AUTOSAR XML (schema 00046)
package /EcuExtract
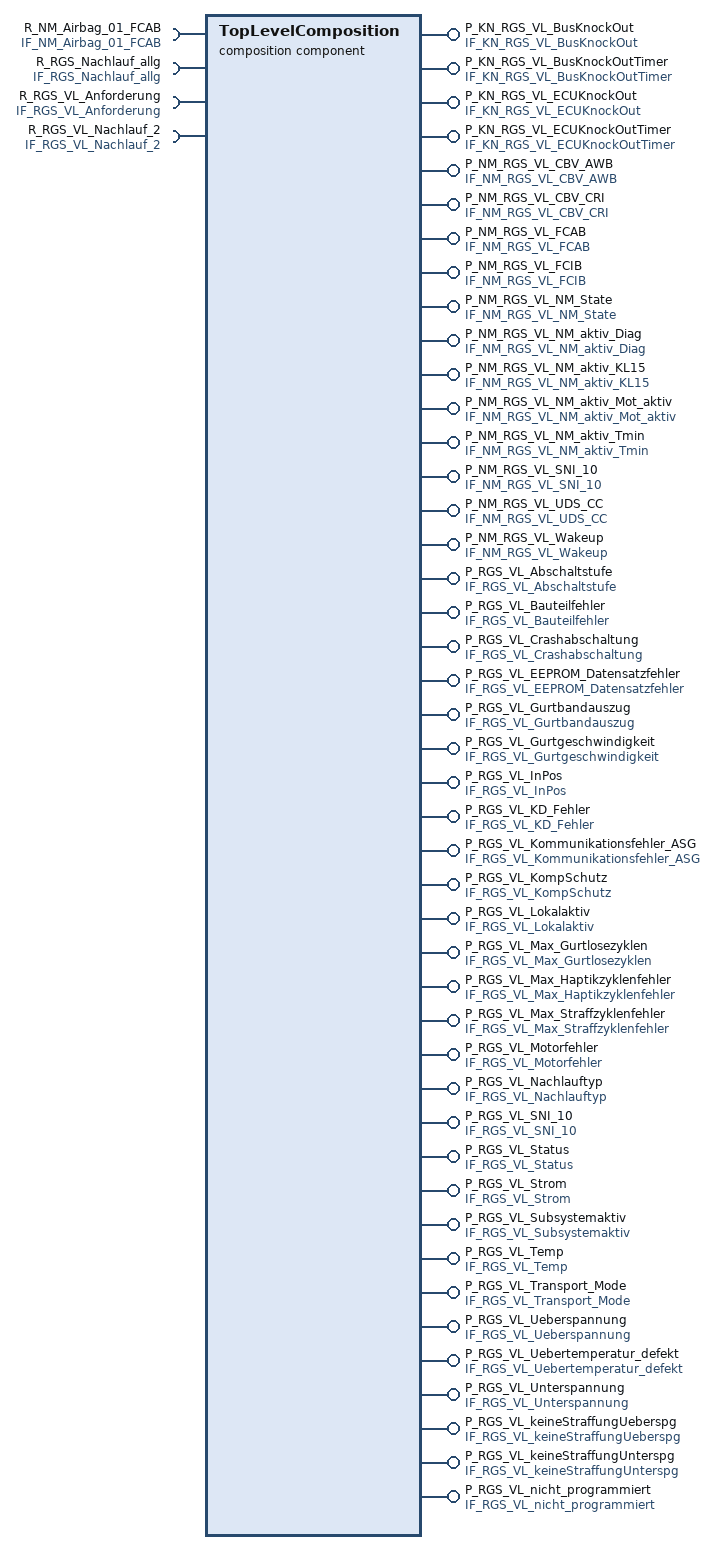
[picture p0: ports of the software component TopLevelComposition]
  composition sw component type TopLevelComposition
    44 x provide port:
      P_KN_RGS_VL_BusKnockOut: provided-interface=IF_KN_RGS_VL_BusKnockOut
      P_KN_RGS_VL_BusKnockOutTimer: provided-interface=IF_KN_RGS_VL_BusKnockOutTimer
      P_KN_RGS_VL_ECUKnockOut: provided-interface=IF_KN_RGS_VL_ECUKnockOut
      P_KN_RGS_VL_ECUKnockOutTimer: provided-interface=IF_KN_RGS_VL_ECUKnockOutTimer
      P_NM_RGS_VL_CBV_AWB: provided-interface=IF_NM_RGS_VL_CBV_AWB
      P_NM_RGS_VL_CBV_CRI: provided-interface=IF_NM_RGS_VL_CBV_CRI
      P_NM_RGS_VL_FCAB: provided-interface=IF_NM_RGS_VL_FCAB
      P_NM_RGS_VL_FCIB: provided-interface=IF_NM_RGS_VL_FCIB
      P_NM_RGS_VL_NM_State: provided-interface=IF_NM_RGS_VL_NM_State
      P_NM_RGS_VL_NM_aktiv_Diag: provided-interface=IF_NM_RGS_VL_NM_aktiv_Diag
      P_NM_RGS_VL_NM_aktiv_KL15: provided-interface=IF_NM_RGS_VL_NM_aktiv_KL15
      P_NM_RGS_VL_NM_aktiv_Mot_aktiv: provided-interface=IF_NM_RGS_VL_NM_aktiv_Mot_aktiv
      P_NM_RGS_VL_NM_aktiv_Tmin: provided-interface=IF_NM_RGS_VL_NM_aktiv_Tmin
      P_NM_RGS_VL_SNI_10: provided-interface=IF_NM_RGS_VL_SNI_10
      P_NM_RGS_VL_UDS_CC: provided-interface=IF_NM_RGS_VL_UDS_CC
      P_NM_RGS_VL_Wakeup: provided-interface=IF_NM_RGS_VL_Wakeup
      P_RGS_VL_Abschaltstufe: provided-interface=IF_RGS_VL_Abschaltstufe
      P_RGS_VL_Bauteilfehler: provided-interface=IF_RGS_VL_Bauteilfehler
      P_RGS_VL_Crashabschaltung: provided-interface=IF_RGS_VL_Crashabschaltung
      P_RGS_VL_EEPROM_Datensatzfehler: provided-interface=IF_RGS_VL_EEPROM_Datensatzfehler
      P_RGS_VL_Gurtbandauszug: provided-interface=IF_RGS_VL_Gurtbandauszug
      P_RGS_VL_Gurtgeschwindigkeit: provided-interface=IF_RGS_VL_Gurtgeschwindigkeit
      P_RGS_VL_InPos: provided-interface=IF_RGS_VL_InPos
      P_RGS_VL_KD_Fehler: provided-interface=IF_RGS_VL_KD_Fehler
      P_RGS_VL_Kommunikationsfehler_ASG: provided-interface=IF_RGS_VL_Kommunikationsfehler_ASG
      P_RGS_VL_KompSchutz: provided-interface=IF_RGS_VL_KompSchutz
      P_RGS_VL_Lokalaktiv: provided-interface=IF_RGS_VL_Lokalaktiv
      P_RGS_VL_Max_Gurtlosezyklen: provided-interface=IF_RGS_VL_Max_Gurtlosezyklen
      P_RGS_VL_Max_Haptikzyklenfehler: provided-interface=IF_RGS_VL_Max_Haptikzyklenfehler
      P_RGS_VL_Max_Straffzyklenfehler: provided-interface=IF_RGS_VL_Max_Straffzyklenfehler
      P_RGS_VL_Motorfehler: provided-interface=IF_RGS_VL_Motorfehler
      P_RGS_VL_Nachlauftyp: provided-interface=IF_RGS_VL_Nachlauftyp
      P_RGS_VL_SNI_10: provided-interface=IF_RGS_VL_SNI_10
      P_RGS_VL_Status: provided-interface=IF_RGS_VL_Status
      P_RGS_VL_Strom: provided-interface=IF_RGS_VL_Strom
      P_RGS_VL_Subsystemaktiv: provided-interface=IF_RGS_VL_Subsystemaktiv
      P_RGS_VL_Temp: provided-interface=IF_RGS_VL_Temp
      P_RGS_VL_Transport_Mode: provided-interface=IF_RGS_VL_Transport_Mode
      P_RGS_VL_Ueberspannung: provided-interface=IF_RGS_VL_Ueberspannung
      P_RGS_VL_Uebertemperatur_defekt: provided-interface=IF_RGS_VL_Uebertemperatur_defekt
      P_RGS_VL_Unterspannung: provided-interface=IF_RGS_VL_Unterspannung
      P_RGS_VL_keineStraffungUeberspg: provided-interface=IF_RGS_VL_keineStraffungUeberspg
      P_RGS_VL_keineStraffungUnterspg: provided-interface=IF_RGS_VL_keineStraffungUnterspg
      P_RGS_VL_nicht_programmiert: provided-interface=IF_RGS_VL_nicht_programmiert
    4 x require port:
      R_NM_Airbag_01_FCAB: required-interface=IF_NM_Airbag_01_FCAB
      R_RGS_Nachlauf_allg: required-interface=IF_RGS_Nachlauf_allg
      R_RGS_VL_Anforderung: required-interface=IF_RGS_VL_Anforderung
      R_RGS_VL_Nachlauf_2: required-interface=IF_RGS_VL_Nachlauf_2
    11 x component:
      BswM_Prototype: type=BswM
      ComM_Prototype: type=ComM
      Dem_Prototype: type=Dem
      Dcm_Prototype: type=Dcm
      EcuM_Prototype: type=EcuM
      DiagDt_Prototype: type=DiagDt
      NmUsrDt_SwCType_Prototype: type=NmUsrDt_SwCType
      DiagDt_DiagExt_Prototype: type=DiagDt_DiagExt
      BusMon_SwCType_Prototype: type=BusMon_SwCType
      VoltMon_Prototype: type=VoltMon
      TestSwc: type=TestSwc_RGS_VL
    delegate TestSwc.P_KN_RGS_VL_BusKnockOut <-> outer port P_KN_RGS_VL_BusKnockOut
    delegate TestSwc.P_KN_RGS_VL_BusKnockOutTimer <-> outer port P_KN_RGS_VL_BusKnockOutTimer
    delegate TestSwc.P_KN_RGS_VL_ECUKnockOut <-> outer port P_KN_RGS_VL_ECUKnockOut
    delegate TestSwc.P_KN_RGS_VL_ECUKnockOutTimer <-> outer port P_KN_RGS_VL_ECUKnockOutTimer
    delegate TestSwc.P_NM_RGS_VL_CBV_AWB <-> outer port P_NM_RGS_VL_CBV_AWB
    delegate TestSwc.P_NM_RGS_VL_CBV_CRI <-> outer port P_NM_RGS_VL_CBV_CRI
    delegate TestSwc.P_NM_RGS_VL_FCAB <-> outer port P_NM_RGS_VL_FCAB
    delegate TestSwc.P_NM_RGS_VL_FCIB <-> outer port P_NM_RGS_VL_FCIB
    delegate TestSwc.P_NM_RGS_VL_NM_State <-> outer port P_NM_RGS_VL_NM_State
    delegate TestSwc.P_NM_RGS_VL_NM_aktiv_Diag <-> outer port P_NM_RGS_VL_NM_aktiv_Diag
    delegate TestSwc.P_NM_RGS_VL_NM_aktiv_KL15 <-> outer port P_NM_RGS_VL_NM_aktiv_KL15
    delegate TestSwc.P_NM_RGS_VL_NM_aktiv_Mot_aktiv <-> outer port P_NM_RGS_VL_NM_aktiv_Mot_aktiv
    delegate TestSwc.P_NM_RGS_VL_NM_aktiv_Tmin <-> outer port P_NM_RGS_VL_NM_aktiv_Tmin
    delegate TestSwc.P_NM_RGS_VL_SNI_10 <-> outer port P_NM_RGS_VL_SNI_10
    delegate TestSwc.P_NM_RGS_VL_UDS_CC <-> outer port P_NM_RGS_VL_UDS_CC
    delegate TestSwc.P_NM_RGS_VL_Wakeup <-> outer port P_NM_RGS_VL_Wakeup
    delegate TestSwc.P_RGS_VL_Abschaltstufe <-> outer port P_RGS_VL_Abschaltstufe
    delegate TestSwc.P_RGS_VL_Bauteilfehler <-> outer port P_RGS_VL_Bauteilfehler
    delegate TestSwc.P_RGS_VL_Crashabschaltung <-> outer port P_RGS_VL_Crashabschaltung
    delegate TestSwc.P_RGS_VL_EEPROM_Datensatzfehler <-> outer port P_RGS_VL_EEPROM_Datensatzfehler
    delegate TestSwc.P_RGS_VL_Gurtbandauszug <-> outer port P_RGS_VL_Gurtbandauszug
    delegate TestSwc.P_RGS_VL_Gurtgeschwindigkeit <-> outer port P_RGS_VL_Gurtgeschwindigkeit
    delegate TestSwc.P_RGS_VL_InPos <-> outer port P_RGS_VL_InPos
    delegate TestSwc.P_RGS_VL_KD_Fehler <-> outer port P_RGS_VL_KD_Fehler
    delegate TestSwc.P_RGS_VL_Kommunikationsfehler_ASG <-> outer port P_RGS_VL_Kommunikationsfehler_ASG
    delegate TestSwc.P_RGS_VL_KompSchutz <-> outer port P_RGS_VL_KompSchutz
    delegate TestSwc.P_RGS_VL_Lokalaktiv <-> outer port P_RGS_VL_Lokalaktiv
    delegate TestSwc.P_RGS_VL_Max_Gurtlosezyklen <-> outer port P_RGS_VL_Max_Gurtlosezyklen
    delegate TestSwc.P_RGS_VL_Max_Haptikzyklenfehler <-> outer port P_RGS_VL_Max_Haptikzyklenfehler
    delegate TestSwc.P_RGS_VL_Max_Straffzyklenfehler <-> outer port P_RGS_VL_Max_Straffzyklenfehler
    delegate TestSwc.P_RGS_VL_Motorfehler <-> outer port P_RGS_VL_Motorfehler
    delegate TestSwc.P_RGS_VL_Nachlauftyp <-> outer port P_RGS_VL_Nachlauftyp
    delegate TestSwc.P_RGS_VL_SNI_10 <-> outer port P_RGS_VL_SNI_10
    delegate TestSwc.P_RGS_VL_Status <-> outer port P_RGS_VL_Status
    delegate TestSwc.P_RGS_VL_Strom <-> outer port P_RGS_VL_Strom
    delegate TestSwc.P_RGS_VL_Subsystemaktiv <-> outer port P_RGS_VL_Subsystemaktiv
    delegate TestSwc.P_RGS_VL_Temp <-> outer port P_RGS_VL_Temp
    delegate TestSwc.P_RGS_VL_Transport_Mode <-> outer port P_RGS_VL_Transport_Mode
    delegate TestSwc.P_RGS_VL_Ueberspannung <-> outer port P_RGS_VL_Ueberspannung
    delegate TestSwc.P_RGS_VL_Uebertemperatur_defekt <-> outer port P_RGS_VL_Uebertemperatur_defekt
    delegate TestSwc.P_RGS_VL_Unterspannung <-> outer port P_RGS_VL_Unterspannung
    delegate TestSwc.P_RGS_VL_keineStraffungUeberspg <-> outer port P_RGS_VL_keineStraffungUeberspg
    delegate TestSwc.P_RGS_VL_keineStraffungUnterspg <-> outer port P_RGS_VL_keineStraffungUnterspg
    delegate TestSwc.P_RGS_VL_nicht_programmiert <-> outer port P_RGS_VL_nicht_programmiert
    delegate TestSwc.R_NM_Airbag_01_FCAB <-> outer port R_NM_Airbag_01_FCAB
    delegate TestSwc.R_RGS_Nachlauf_allg <-> outer port R_RGS_Nachlauf_allg
    delegate TestSwc.R_RGS_VL_Anforderung <-> outer port R_RGS_VL_Anforderung
    delegate TestSwc.R_RGS_VL_Nachlauf_2 <-> outer port R_RGS_VL_Nachlauf_2
  system ECU: category=ECU_EXTRACT, system-version=1.0.0
    48 x system mapping:
      DataMappings_P_KN_RGS_VL_BusKnockOut: sender-receiver-to-signal-mapping{data-element=TopLevelCompositionPrototype.P_KN_RGS_VL_BusKnockOut.KN_RGS_VL_BusKnockOut, system-signal=KN_RGS_VL_BusKnockOut}
      DataMappings_P_KN_RGS_VL_BusKnockOutTimer: sender-receiver-to-signal-mapping{data-element=TopLevelCompositionPrototype.P_KN_RGS_VL_BusKnockOutTimer.KN_RGS_VL_BusKnockOutTimer, system-signal=KN_RGS_VL_BusKnockOutTimer}
      DataMappings_P_KN_RGS_VL_ECUKnockOut: sender-receiver-to-signal-mapping{data-element=TopLevelCompositionPrototype.P_KN_RGS_VL_ECUKnockOut.KN_RGS_VL_ECUKnockOut, system-signal=KN_RGS_VL_ECUKnockOut}
      DataMappings_P_KN_RGS_VL_ECUKnockOutTimer: sender-receiver-to-signal-mapping{data-element=TopLevelCompositionPrototype.P_KN_RGS_VL_ECUKnockOutTimer.KN_RGS_VL_ECUKnockOutTimer, system-signal=KN_RGS_VL_ECUKnockOutTimer}
      DataMappings_P_NM_RGS_VL_CBV_AWB: sender-receiver-to-signal-mapping{data-element=TopLevelCompositionPrototype.P_NM_RGS_VL_CBV_AWB.NM_RGS_VL_CBV_AWB, system-signal=NM_RGS_VL_CBV_AWB}
      DataMappings_P_NM_RGS_VL_CBV_CRI: sender-receiver-to-signal-mapping{data-element=TopLevelCompositionPrototype.P_NM_RGS_VL_CBV_CRI.NM_RGS_VL_CBV_CRI, system-signal=NM_RGS_VL_CBV_CRI}
      DataMappings_P_NM_RGS_VL_FCAB: sender-receiver-to-signal-mapping{data-element=TopLevelCompositionPrototype.P_NM_RGS_VL_FCAB.NM_RGS_VL_FCAB, system-signal=NM_RGS_VL_FCAB}
      DataMappings_P_NM_RGS_VL_FCIB: sender-receiver-to-signal-mapping{data-element=TopLevelCompositionPrototype.P_NM_RGS_VL_FCIB.NM_RGS_VL_FCIB, system-signal=NM_RGS_VL_FCIB}
      DataMappings_P_NM_RGS_VL_NM_State: sender-receiver-to-signal-mapping{data-element=TopLevelCompositionPrototype.P_NM_RGS_VL_NM_State.NM_RGS_VL_NM_State, system-signal=NM_RGS_VL_NM_State}
      DataMappings_P_NM_RGS_VL_NM_aktiv_Diag: sender-receiver-to-signal-mapping{data-element=TopLevelCompositionPrototype.P_NM_RGS_VL_NM_aktiv_Diag.NM_RGS_VL_NM_aktiv_Diag, system-signal=NM_RGS_VL_NM_aktiv_Diag}
      DataMappings_P_NM_RGS_VL_NM_aktiv_KL15: sender-receiver-to-signal-mapping{data-element=TopLevelCompositionPrototype.P_NM_RGS_VL_NM_aktiv_KL15.NM_RGS_VL_NM_aktiv_KL15, system-signal=NM_RGS_VL_NM_aktiv_KL15}
      DataMappings_P_NM_RGS_VL_NM_aktiv_Mot_aktiv: sender-receiver-to-signal-mapping{data-element=TopLevelCompositionPrototype.P_NM_RGS_VL_NM_aktiv_Mot_aktiv.NM_RGS_VL_NM_aktiv_Mot_aktiv, system-signal=NM_RGS_VL_NM_aktiv_Mot_aktiv}
      DataMappings_P_NM_RGS_VL_NM_aktiv_Tmin: sender-receiver-to-signal-mapping{data-element=TopLevelCompositionPrototype.P_NM_RGS_VL_NM_aktiv_Tmin.NM_RGS_VL_NM_aktiv_Tmin, system-signal=NM_RGS_VL_NM_aktiv_Tmin}
      DataMappings_P_NM_RGS_VL_SNI_10: sender-receiver-to-signal-mapping{data-element=TopLevelCompositionPrototype.P_NM_RGS_VL_SNI_10.NM_RGS_VL_SNI_10, system-signal=NM_RGS_VL_SNI_10}
      DataMappings_P_NM_RGS_VL_UDS_CC: sender-receiver-to-signal-mapping{data-element=TopLevelCompositionPrototype.P_NM_RGS_VL_UDS_CC.NM_RGS_VL_UDS_CC, system-signal=NM_RGS_VL_UDS_CC}
      DataMappings_P_NM_RGS_VL_Wakeup: sender-receiver-to-signal-mapping{data-element=TopLevelCompositionPrototype.P_NM_RGS_VL_Wakeup.NM_RGS_VL_Wakeup, system-signal=NM_RGS_VL_Wakeup}
      DataMappings_P_RGS_VL_Abschaltstufe: sender-receiver-to-signal-mapping{data-element=TopLevelCompositionPrototype.P_RGS_VL_Abschaltstufe.RGS_VL_Abschaltstufe, system-signal=RGS_VL_Abschaltstufe}
      DataMappings_P_RGS_VL_Bauteilfehler: sender-receiver-to-signal-mapping{data-element=TopLevelCompositionPrototype.P_RGS_VL_Bauteilfehler.RGS_VL_Bauteilfehler, system-signal=RGS_VL_Bauteilfehler}
      DataMappings_P_RGS_VL_Crashabschaltung: sender-receiver-to-signal-mapping{data-element=TopLevelCompositionPrototype.P_RGS_VL_Crashabschaltung.RGS_VL_Crashabschaltung, system-signal=RGS_VL_Crashabschaltung}
      DataMappings_P_RGS_VL_EEPROM_Datensatzfehler: sender-receiver-to-signal-mapping{data-element=TopLevelCompositionPrototype.P_RGS_VL_EEPROM_Datensatzfehler.RGS_VL_EEPROM_Datensatzfehler, system-signal=RGS_VL_EEPROM_Datensatzfehler}
      DataMappings_P_RGS_VL_Gurtbandauszug: sender-receiver-to-signal-mapping{data-element=TopLevelCompositionPrototype.P_RGS_VL_Gurtbandauszug.RGS_VL_Gurtbandauszug, system-signal=RGS_VL_Gurtbandauszug}
      DataMappings_P_RGS_VL_Gurtgeschwindigkeit: sender-receiver-to-signal-mapping{data-element=TopLevelCompositionPrototype.P_RGS_VL_Gurtgeschwindigkeit.RGS_VL_Gurtgeschwindigkeit, system-signal=RGS_VL_Gurtgeschwindigkeit}
      DataMappings_P_RGS_VL_InPos: sender-receiver-to-signal-mapping{data-element=TopLevelCompositionPrototype.P_RGS_VL_InPos.RGS_VL_InPos, system-signal=RGS_VL_InPos}
      DataMappings_P_RGS_VL_KD_Fehler: sender-receiver-to-signal-mapping{data-element=TopLevelCompositionPrototype.P_RGS_VL_KD_Fehler.RGS_VL_KD_Fehler, system-signal=RGS_VL_KD_Fehler}
      DataMappings_P_RGS_VL_Kommunikationsfehler_ASG: sender-receiver-to-signal-mapping{data-element=TopLevelCompositionPrototype.P_RGS_VL_Kommunikationsfehler_ASG.RGS_VL_Kommunikationsfehler_ASG, system-signal=RGS_VL_Kommunikationsfehler_ASG}
      DataMappings_P_RGS_VL_KompSchutz: sender-receiver-to-signal-mapping{data-element=TopLevelCompositionPrototype.P_RGS_VL_KompSchutz.RGS_VL_KompSchutz, system-signal=RGS_VL_KompSchutz}
      DataMappings_P_RGS_VL_Lokalaktiv: sender-receiver-to-signal-mapping{data-element=TopLevelCompositionPrototype.P_RGS_VL_Lokalaktiv.RGS_VL_Lokalaktiv, system-signal=RGS_VL_Lokalaktiv}
      DataMappings_P_RGS_VL_Max_Gurtlosezyklen: sender-receiver-to-signal-mapping{data-element=TopLevelCompositionPrototype.P_RGS_VL_Max_Gurtlosezyklen.RGS_VL_Max_Gurtlosezyklen, system-signal=RGS_VL_Max_Gurtlosezyklen}
      DataMappings_P_RGS_VL_Max_Haptikzyklenfehler: sender-receiver-to-signal-mapping{data-element=TopLevelCompositionPrototype.P_RGS_VL_Max_Haptikzyklenfehler.RGS_VL_Max_Haptikzyklenfehler, system-signal=RGS_VL_Max_Haptikzyklenfehler}
      DataMappings_P_RGS_VL_Max_Straffzyklenfehler: sender-receiver-to-signal-mapping{data-element=TopLevelCompositionPrototype.P_RGS_VL_Max_Straffzyklenfehler.RGS_VL_Max_Straffzyklenfehler, system-signal=RGS_VL_Max_Straffzyklenfehler}
      DataMappings_P_RGS_VL_Motorfehler: sender-receiver-to-signal-mapping{data-element=TopLevelCompositionPrototype.P_RGS_VL_Motorfehler.RGS_VL_Motorfehler, system-signal=RGS_VL_Motorfehler}
      DataMappings_P_RGS_VL_Nachlauftyp: sender-receiver-to-signal-mapping{data-element=TopLevelCompositionPrototype.P_RGS_VL_Nachlauftyp.RGS_VL_Nachlauftyp, system-signal=RGS_VL_Nachlauftyp}
      DataMappings_P_RGS_VL_SNI_10: sender-receiver-to-signal-mapping{data-element=TopLevelCompositionPrototype.P_RGS_VL_SNI_10.RGS_VL_SNI_10, system-signal=RGS_VL_SNI_10}
      DataMappings_P_RGS_VL_Status: sender-receiver-to-signal-mapping{data-element=TopLevelCompositionPrototype.P_RGS_VL_Status.RGS_VL_Status, system-signal=RGS_VL_Status}
      DataMappings_P_RGS_VL_Strom: sender-receiver-to-signal-mapping{data-element=TopLevelCompositionPrototype.P_RGS_VL_Strom.RGS_VL_Strom, system-signal=RGS_VL_Strom}
      DataMappings_P_RGS_VL_Subsystemaktiv: sender-receiver-to-signal-mapping{data-element=TopLevelCompositionPrototype.P_RGS_VL_Subsystemaktiv.RGS_VL_Subsystemaktiv, system-signal=RGS_VL_Subsystemaktiv}
      DataMappings_P_RGS_VL_Temp: sender-receiver-to-signal-mapping{data-element=TopLevelCompositionPrototype.P_RGS_VL_Temp.RGS_VL_Temp, system-signal=RGS_VL_Temp}
      DataMappings_P_RGS_VL_Transport_Mode: sender-receiver-to-signal-mapping{data-element=TopLevelCompositionPrototype.P_RGS_VL_Transport_Mode.RGS_VL_Transport_Mode, system-signal=RGS_VL_Transport_Mode}
      DataMappings_P_RGS_VL_Ueberspannung: sender-receiver-to-signal-mapping{data-element=TopLevelCompositionPrototype.P_RGS_VL_Ueberspannung.RGS_VL_Ueberspannung, system-signal=RGS_VL_Ueberspannung}
      DataMappings_P_RGS_VL_Uebertemperatur_defekt: sender-receiver-to-signal-mapping{data-element=TopLevelCompositionPrototype.P_RGS_VL_Uebertemperatur_defekt.RGS_VL_Uebertemperatur_defekt, system-signal=RGS_VL_Uebertemperatur_defekt}
      DataMappings_P_RGS_VL_Unterspannung: sender-receiver-to-signal-mapping{data-element=TopLevelCompositionPrototype.P_RGS_VL_Unterspannung.RGS_VL_Unterspannung, system-signal=RGS_VL_Unterspannung}
      DataMappings_P_RGS_VL_keineStraffungUeberspg: sender-receiver-to-signal-mapping{data-element=TopLevelCompositionPrototype.P_RGS_VL_keineStraffungUeberspg.RGS_VL_keineStraffungUeberspg, system-signal=RGS_VL_keineStraffungUeberspg}
      DataMappings_P_RGS_VL_keineStraffungUnterspg: sender-receiver-to-signal-mapping{data-element=TopLevelCompositionPrototype.P_RGS_VL_keineStraffungUnterspg.RGS_VL_keineStraffungUnterspg, system-signal=RGS_VL_keineStraffungUnterspg}
      DataMappings_P_RGS_VL_nicht_programmiert: sender-receiver-to-signal-mapping{data-element=TopLevelCompositionPrototype.P_RGS_VL_nicht_programmiert.RGS_VL_nicht_programmiert, system-signal=RGS_VL_nicht_programmiert}
      DataMappings_R_NM_Airbag_01_FCAB: sender-receiver-to-signal-mapping{data-element=TopLevelCompositionPrototype.R_NM_Airbag_01_FCAB.NM_Airbag_01_FCAB, system-signal=NM_Airbag_01_FCAB}
      DataMappings_R_RGS_Nachlauf_allg: sender-receiver-to-signal-mapping{data-element=TopLevelCompositionPrototype.R_RGS_Nachlauf_allg.RGS_Nachlauf_allg, system-signal=RGS_Nachlauf_allg}
      DataMappings_R_RGS_VL_Anforderung: sender-receiver-to-signal-mapping{data-element=TopLevelCompositionPrototype.R_RGS_VL_Anforderung.RGS_VL_Anforderung, system-signal=RGS_VL_Anforderung}
      DataMappings_R_RGS_VL_Nachlauf_2: sender-receiver-to-signal-mapping{data-element=TopLevelCompositionPrototype.R_RGS_VL_Nachlauf_2.RGS_VL_Nachlauf_2, system-signal=RGS_VL_Nachlauf_2}
    root-software-compositions:
      root sw composition prototype TopLevelCompositionPrototype: flat-map=FlatMap, software-composition=TopLevelComposition
  flat map FlatMap
    187 x flat instance descriptor:
      BswM_Prototype_0: upstream-reference=Geltungsbereich_E3_1_2_Premium.BswM_Prototype, ecu-extract-reference=TopLevelCompositionPrototype.BswM_Prototype
      BswM_ModeSwitchPort_BswM_SwitchPort_Rte_1: upstream-reference=BswM_Prototype.Geltungsbereich_E3_1_2_Premium.BswM_ModeSwitchPort_BswM_SwitchPort_Rte, ecu-extract-reference=BswM_Prototype.TopLevelCompositionPrototype.BswM_ModeSwitchPort_BswM_SwitchPort_Rte
      BswM_ModeRequestPort_BswMRteModeRequestPort_AppStateMode_2: upstream-reference=BswM_Prototype.Geltungsbereich_E3_1_2_Premium.BswM_ModeRequestPort_BswMRteModeRequestPort_AppStateMode, ecu-extract-reference=BswM_Prototype.TopLevelCompositionPrototype.BswM_ModeRequestPort_BswMRteModeRequestPort_AppStateMode
      If_AppStateRequestMode_3: upstream-reference=BswM_ModeRequestPort_BswMRteModeRequestPort_AppStateMode.BswM_Prototype.Geltungsbereich_E3_1_2_Premium.If_AppStateRequestMode, ecu-extract-reference=BswM_ModeRequestPort_BswMRteModeRequestPort_AppStateMode.BswM_Prototype.TopLevelCompositionPrototype.If_AppStateRequestMode
      ModeNotificationPort_BswM_ModeReqPort_AppState_4: upstream-reference=BswM_Prototype.Geltungsbereich_E3_1_2_Premium.ModeNotificationPort_BswM_ModeReqPort_AppState, ecu-extract-reference=BswM_Prototype.TopLevelCompositionPrototype.ModeNotificationPort_BswM_ModeReqPort_AppState
      ComM_Prototype_5: upstream-reference=Geltungsbereich_E3_1_2_Premium.ComM_Prototype, ecu-extract-reference=TopLevelCompositionPrototype.ComM_Prototype
      UM_ComMUser_0_6: upstream-reference=ComM_Prototype.Geltungsbereich_E3_1_2_Premium.UM_ComMUser_0, ecu-extract-reference=ComM_Prototype.TopLevelCompositionPrototype.UM_ComMUser_0
      UR_ComMUser_0_7: upstream-reference=ComM_Prototype.Geltungsbereich_E3_1_2_Premium.UR_ComMUser_0, ecu-extract-reference=ComM_Prototype.TopLevelCompositionPrototype.UR_ComMUser_0
      Dem_Prototype_8: upstream-reference=Geltungsbereich_E3_1_2_Premium.Dem_Prototype, ecu-extract-reference=TopLevelCompositionPrototype.Dem_Prototype
      ASR42_EvtInfo_ECUM_E_RAM_CHECK_FAILED_9: upstream-reference=Dem_Prototype.Geltungsbereich_E3_1_2_Premium.ASR42_EvtInfo_ECUM_E_RAM_CHECK_FAILED, ecu-extract-reference=Dem_Prototype.TopLevelCompositionPrototype.ASR42_EvtInfo_ECUM_E_RAM_CHECK_FAILED
      ASR42_EvtInfo_MCU_E_TIMEOUT_FAILURE_10: upstream-reference=Dem_Prototype.Geltungsbereich_E3_1_2_Premium.ASR42_EvtInfo_MCU_E_TIMEOUT_FAILURE, ecu-extract-reference=Dem_Prototype.TopLevelCompositionPrototype.ASR42_EvtInfo_MCU_E_TIMEOUT_FAILURE
      ASR42_EvtInfo_MCU_E_CLOCK_FAILURE_11: upstream-reference=Dem_Prototype.Geltungsbereich_E3_1_2_Premium.ASR42_EvtInfo_MCU_E_CLOCK_FAILURE, ecu-extract-reference=Dem_Prototype.TopLevelCompositionPrototype.ASR42_EvtInfo_MCU_E_CLOCK_FAILURE
      ASR42_EvtInfo_CANSM_E_BUS_OFF_0_12: upstream-reference=Dem_Prototype.Geltungsbereich_E3_1_2_Premium.ASR42_EvtInfo_CANSM_E_BUS_OFF_0, ecu-extract-reference=Dem_Prototype.TopLevelCompositionPrototype.ASR42_EvtInfo_CANSM_E_BUS_OFF_0
      ASR42_GeneralEvtInfo_13: upstream-reference=Dem_Prototype.Geltungsbereich_E3_1_2_Premium.ASR42_GeneralEvtInfo, ecu-extract-reference=Dem_Prototype.TopLevelCompositionPrototype.ASR42_GeneralEvtInfo
      ASR42_OpCycle_DEM_OPCYC_POWER_14: upstream-reference=Dem_Prototype.Geltungsbereich_E3_1_2_Premium.ASR42_OpCycle_DEM_OPCYC_POWER, ecu-extract-reference=Dem_Prototype.TopLevelCompositionPrototype.ASR42_OpCycle_DEM_OPCYC_POWER
      ASR42_OverflowIndPrimaryMemory_15: upstream-reference=Dem_Prototype.Geltungsbereich_E3_1_2_Premium.ASR42_OverflowIndPrimaryMemory, ecu-extract-reference=Dem_Prototype.TopLevelCompositionPrototype.ASR42_OverflowIndPrimaryMemory
      ASR42_PowerTakeOffStatus_16: upstream-reference=Dem_Prototype.Geltungsbereich_E3_1_2_Premium.ASR42_PowerTakeOffStatus, ecu-extract-reference=Dem_Prototype.TopLevelCompositionPrototype.ASR42_PowerTakeOffStatus
      EvtInfo_ECUM_E_RAM_CHECK_FAILED_17: upstream-reference=Dem_Prototype.Geltungsbereich_E3_1_2_Premium.EvtInfo_ECUM_E_RAM_CHECK_FAILED, ecu-extract-reference=Dem_Prototype.TopLevelCompositionPrototype.EvtInfo_ECUM_E_RAM_CHECK_FAILED
      EvtInfo_MCU_E_TIMEOUT_FAILURE_18: upstream-reference=Dem_Prototype.Geltungsbereich_E3_1_2_Premium.EvtInfo_MCU_E_TIMEOUT_FAILURE, ecu-extract-reference=Dem_Prototype.TopLevelCompositionPrototype.EvtInfo_MCU_E_TIMEOUT_FAILURE
      EvtInfo_MCU_E_CLOCK_FAILURE_19: upstream-reference=Dem_Prototype.Geltungsbereich_E3_1_2_Premium.EvtInfo_MCU_E_CLOCK_FAILURE, ecu-extract-reference=Dem_Prototype.TopLevelCompositionPrototype.EvtInfo_MCU_E_CLOCK_FAILURE
      EvtInfo_CANSM_E_BUS_OFF_0_20: upstream-reference=Dem_Prototype.Geltungsbereich_E3_1_2_Premium.EvtInfo_CANSM_E_BUS_OFF_0, ecu-extract-reference=Dem_Prototype.TopLevelCompositionPrototype.EvtInfo_CANSM_E_BUS_OFF_0
      GeneralEvtInfo_21: upstream-reference=Dem_Prototype.Geltungsbereich_E3_1_2_Premium.GeneralEvtInfo, ecu-extract-reference=Dem_Prototype.TopLevelCompositionPrototype.GeneralEvtInfo
      OpCycle_DEM_OPCYC_POWER_22: upstream-reference=Dem_Prototype.Geltungsbereich_E3_1_2_Premium.OpCycle_DEM_OPCYC_POWER, ecu-extract-reference=Dem_Prototype.TopLevelCompositionPrototype.OpCycle_DEM_OPCYC_POWER
      OverflowIndPrimaryMemory_23: upstream-reference=Dem_Prototype.Geltungsbereich_E3_1_2_Premium.OverflowIndPrimaryMemory, ecu-extract-reference=Dem_Prototype.TopLevelCompositionPrototype.OverflowIndPrimaryMemory
      Dcm_24: upstream-reference=Dem_Prototype.Geltungsbereich_E3_1_2_Premium.Dcm, ecu-extract-reference=Dem_Prototype.TopLevelCompositionPrototype.Dcm
      CddIf_25: upstream-reference=Dem_Prototype.Geltungsbereich_E3_1_2_Premium.CddIf, ecu-extract-reference=Dem_Prototype.TopLevelCompositionPrototype.CddIf
      PowerTakeOffStatus_26: upstream-reference=Dem_Prototype.Geltungsbereich_E3_1_2_Premium.PowerTakeOffStatus, ecu-extract-reference=Dem_Prototype.TopLevelCompositionPrototype.PowerTakeOffStatus
      Dcm_Prototype_27: upstream-reference=Geltungsbereich_E3_1_2_Premium.Dcm_Prototype, ecu-extract-reference=TopLevelCompositionPrototype.Dcm_Prototype
      DCMServices_28: upstream-reference=Dcm_Prototype.Geltungsbereich_E3_1_2_Premium.DCMServices, ecu-extract-reference=Dcm_Prototype.TopLevelCompositionPrototype.DCMServices
      EcuM_Prototype_29: upstream-reference=Geltungsbereich_E3_1_2_Premium.EcuM_Prototype, ecu-extract-reference=TopLevelCompositionPrototype.EcuM_Prototype
      shutdownTarget_30: upstream-reference=EcuM_Prototype.Geltungsbereich_E3_1_2_Premium.shutdownTarget, ecu-extract-reference=EcuM_Prototype.TopLevelCompositionPrototype.shutdownTarget
      bootTarget_31: upstream-reference=EcuM_Prototype.Geltungsbereich_E3_1_2_Premium.bootTarget, ecu-extract-reference=EcuM_Prototype.TopLevelCompositionPrototype.bootTarget
      DiagDt_Prototype_32: upstream-reference=Geltungsbereich_E3_1_2_Premium.DiagDt_Prototype, ecu-extract-reference=TopLevelCompositionPrototype.DiagDt_Prototype
      Port_Diagnose1_33: upstream-reference=DiagDt_Prototype.Geltungsbereich_E3_1_2_Premium.Port_Diagnose1, ecu-extract-reference=DiagDt_Prototype.TopLevelCompositionPrototype.Port_Diagnose1
      SIG_KBI_Kilometerstand_34: upstream-reference=Port_Diagnose1.DiagDt_Prototype.Geltungsbereich_E3_1_2_Premium.SIG_KBI_Kilometerstand, ecu-extract-reference=Port_Diagnose1.DiagDt_Prototype.TopLevelCompositionPrototype.SIG_KBI_Kilometerstand
      SIG_UH_Jahr_35: upstream-reference=Port_Diagnose1.DiagDt_Prototype.Geltungsbereich_E3_1_2_Premium.SIG_UH_Jahr, ecu-extract-reference=Port_Diagnose1.DiagDt_Prototype.TopLevelCompositionPrototype.SIG_UH_Jahr
      SIG_UH_Monat_36: upstream-reference=Port_Diagnose1.DiagDt_Prototype.Geltungsbereich_E3_1_2_Premium.SIG_UH_Monat, ecu-extract-reference=Port_Diagnose1.DiagDt_Prototype.TopLevelCompositionPrototype.SIG_UH_Monat
      SIG_UH_Tag_37: upstream-reference=Port_Diagnose1.DiagDt_Prototype.Geltungsbereich_E3_1_2_Premium.SIG_UH_Tag, ecu-extract-reference=Port_Diagnose1.DiagDt_Prototype.TopLevelCompositionPrototype.SIG_UH_Tag
      SIG_UH_Stunde_38: upstream-reference=Port_Diagnose1.DiagDt_Prototype.Geltungsbereich_E3_1_2_Premium.SIG_UH_Stunde, ecu-extract-reference=Port_Diagnose1.DiagDt_Prototype.TopLevelCompositionPrototype.SIG_UH_Stunde
      SIG_UH_Minute_39: upstream-reference=Port_Diagnose1.DiagDt_Prototype.Geltungsbereich_E3_1_2_Premium.SIG_UH_Minute, ecu-extract-reference=Port_Diagnose1.DiagDt_Prototype.TopLevelCompositionPrototype.SIG_UH_Minute
      SIG_UH_Sekunde_40: upstream-reference=Port_Diagnose1.DiagDt_Prototype.Geltungsbereich_E3_1_2_Premium.SIG_UH_Sekunde, ecu-extract-reference=Port_Diagnose1.DiagDt_Prototype.TopLevelCompositionPrototype.SIG_UH_Sekunde
      DidServices_StandardFreezeFrame_41: upstream-reference=DiagDt_Prototype.Geltungsbereich_E3_1_2_Premium.DidServices_StandardFreezeFrame, ecu-extract-reference=DiagDt_Prototype.TopLevelCompositionPrototype.DidServices_StandardFreezeFrame
      CheckEnvConditionReadPort_42: upstream-reference=DiagDt_Prototype.Geltungsbereich_E3_1_2_Premium.CheckEnvConditionReadPort, ecu-extract-reference=DiagDt_Prototype.TopLevelCompositionPrototype.CheckEnvConditionReadPort
      currentMode_43: upstream-reference=DiagDt_Prototype.Geltungsbereich_E3_1_2_Premium.currentMode, ecu-extract-reference=DiagDt_Prototype.TopLevelCompositionPrototype.currentMode
      PS_NvM_DiagDt_Mileage_44: upstream-reference=DiagDt_Prototype.Geltungsbereich_E3_1_2_Premium.PS_NvM_DiagDt_Mileage, ecu-extract-reference=DiagDt_Prototype.TopLevelCompositionPrototype.PS_NvM_DiagDt_Mileage
      NmUsrDt_SwCType_Prototype_45: upstream-reference=Geltungsbereich_E3_1_2_Premium.NmUsrDt_SwCType_Prototype, ecu-extract-reference=TopLevelCompositionPrototype.NmUsrDt_SwCType_Prototype
      RPORT_WU_0_46: upstream-reference=NmUsrDt_SwCType_Prototype.Geltungsbereich_E3_1_2_Premium.RPORT_WU_0, ecu-extract-reference=NmUsrDt_SwCType_Prototype.TopLevelCompositionPrototype.RPORT_WU_0
      DCM_Session_PORT_47: upstream-reference=NmUsrDt_SwCType_Prototype.Geltungsbereich_E3_1_2_Premium.DCM_Session_PORT, ecu-extract-reference=NmUsrDt_SwCType_Prototype.TopLevelCompositionPrototype.DCM_Session_PORT
      T_NM_Diag_Retrigger_48: upstream-reference=NmUsrDt_SwCType_Prototype.Geltungsbereich_E3_1_2_Premium.T_NM_Diag_Retrigger, ecu-extract-reference=NmUsrDt_SwCType_Prototype.TopLevelCompositionPrototype.T_NM_Diag_Retrigger
      Transition35Indication_49: upstream-reference=NmUsrDt_SwCType_Prototype.Geltungsbereich_E3_1_2_Premium.Transition35Indication, ecu-extract-reference=NmUsrDt_SwCType_Prototype.TopLevelCompositionPrototype.Transition35Indication
      currentKL15ModePort_50: upstream-reference=NmUsrDt_SwCType_Prototype.Geltungsbereich_E3_1_2_Premium.currentKL15ModePort, ecu-extract-reference=NmUsrDt_SwCType_Prototype.TopLevelCompositionPrototype.currentKL15ModePort
      RP_DcmCommunicationControl_51: upstream-reference=NmUsrDt_SwCType_Prototype.Geltungsbereich_E3_1_2_Premium.RP_DcmCommunicationControl, ecu-extract-reference=NmUsrDt_SwCType_Prototype.TopLevelCompositionPrototype.RP_DcmCommunicationControl
      RP_CABSignalState_52: upstream-reference=NmUsrDt_SwCType_Prototype.Geltungsbereich_E3_1_2_Premium.RP_CABSignalState, ecu-extract-reference=NmUsrDt_SwCType_Prototype.TopLevelCompositionPrototype.RP_CABSignalState
      PP_T_Diag_Expired_53: upstream-reference=NmUsrDt_SwCType_Prototype.Geltungsbereich_E3_1_2_Premium.PP_T_Diag_Expired, ecu-extract-reference=NmUsrDt_SwCType_Prototype.TopLevelCompositionPrototype.PP_T_Diag_Expired
      PP_T_Diag_Restarted_54: upstream-reference=NmUsrDt_SwCType_Prototype.Geltungsbereich_E3_1_2_Premium.PP_T_Diag_Restarted, ecu-extract-reference=NmUsrDt_SwCType_Prototype.TopLevelCompositionPrototype.PP_T_Diag_Restarted
      DiagDt_DiagExt_Prototype_55: upstream-reference=Geltungsbereich_E3_1_2_Premium.DiagDt_DiagExt_Prototype, ecu-extract-reference=TopLevelCompositionPrototype.DiagDt_DiagExt_Prototype
      ServiceRequestNotification_DiagDt_DiagExt_56: upstream-reference=DiagDt_DiagExt_Prototype.Geltungsbereich_E3_1_2_Premium.ServiceRequestNotification_DiagDt_DiagExt, ecu-extract-reference=DiagDt_DiagExt_Prototype.TopLevelCompositionPrototype.ServiceRequestNotification_DiagDt_DiagExt
      TriggerTNmDiagRestart_57: upstream-reference=DiagDt_DiagExt_Prototype.Geltungsbereich_E3_1_2_Premium.TriggerTNmDiagRestart, ecu-extract-reference=DiagDt_DiagExt_Prototype.TopLevelCompositionPrototype.TriggerTNmDiagRestart
      TriggerTransition35_58: upstream-reference=DiagDt_DiagExt_Prototype.Geltungsbereich_E3_1_2_Premium.TriggerTransition35, ecu-extract-reference=DiagDt_DiagExt_Prototype.TopLevelCompositionPrototype.TriggerTransition35
      DcmServices_59: upstream-reference=DiagDt_DiagExt_Prototype.Geltungsbereich_E3_1_2_Premium.DcmServices, ecu-extract-reference=DiagDt_DiagExt_Prototype.TopLevelCompositionPrototype.DcmServices
      currentKL15ModePort_60: upstream-reference=DiagDt_DiagExt_Prototype.Geltungsbereich_E3_1_2_Premium.currentKL15ModePort, ecu-extract-reference=DiagDt_DiagExt_Prototype.TopLevelCompositionPrototype.currentKL15ModePort
      NM_T_Diag_ExpiredPort_61: upstream-reference=DiagDt_DiagExt_Prototype.Geltungsbereich_E3_1_2_Premium.NM_T_Diag_ExpiredPort, ecu-extract-reference=DiagDt_DiagExt_Prototype.TopLevelCompositionPrototype.NM_T_Diag_ExpiredPort
      NM_T_Diag_RestartedPort_62: upstream-reference=DiagDt_DiagExt_Prototype.Geltungsbereich_E3_1_2_Premium.NM_T_Diag_RestartedPort, ecu-extract-reference=DiagDt_DiagExt_Prototype.TopLevelCompositionPrototype.NM_T_Diag_RestartedPort
      Transition35Possible_63: upstream-reference=DiagDt_DiagExt_Prototype.Geltungsbereich_E3_1_2_Premium.Transition35Possible, ecu-extract-reference=DiagDt_DiagExt_Prototype.TopLevelCompositionPrototype.Transition35Possible
      DCM_Protocol_ResponseOpen_64: upstream-reference=DiagDt_DiagExt_Prototype.Geltungsbereich_E3_1_2_Premium.DCM_Protocol_ResponseOpen, ecu-extract-reference=DiagDt_DiagExt_Prototype.TopLevelCompositionPrototype.DCM_Protocol_ResponseOpen
      BusMon_SwCType_Prototype_65: upstream-reference=Geltungsbereich_E3_1_2_Premium.BusMon_SwCType_Prototype, ecu-extract-reference=TopLevelCompositionPrototype.BusMon_SwCType_Prototype
      KL30_UnderVoltage_66: upstream-reference=BusMon_SwCType_Prototype.Geltungsbereich_E3_1_2_Premium.KL30_UnderVoltage, ecu-extract-reference=BusMon_SwCType_Prototype.TopLevelCompositionPrototype.KL30_UnderVoltage
      KL30_OverVoltage_67: upstream-reference=BusMon_SwCType_Prototype.Geltungsbereich_E3_1_2_Premium.KL30_OverVoltage, ecu-extract-reference=BusMon_SwCType_Prototype.TopLevelCompositionPrototype.KL30_OverVoltage
      Kl15_Status_68: upstream-reference=BusMon_SwCType_Prototype.Geltungsbereich_E3_1_2_Premium.Kl15_Status, ecu-extract-reference=BusMon_SwCType_Prototype.TopLevelCompositionPrototype.Kl15_Status
      kl15_status_69: upstream-reference=Kl15_Status.BusMon_SwCType_Prototype.Geltungsbereich_E3_1_2_Premium.kl15_status, ecu-extract-reference=Kl15_Status.BusMon_SwCType_Prototype.TopLevelCompositionPrototype.kl15_status
      Network_0_ComStatePort_70: upstream-reference=BusMon_SwCType_Prototype.Geltungsbereich_E3_1_2_Premium.Network_0_ComStatePort, ecu-extract-reference=BusMon_SwCType_Prototype.TopLevelCompositionPrototype.Network_0_ComStatePort
      EventSet_Bus_Network_0_71: upstream-reference=BusMon_SwCType_Prototype.Geltungsbereich_E3_1_2_Premium.EventSet_Bus_Network_0, ecu-extract-reference=BusMon_SwCType_Prototype.TopLevelCompositionPrototype.EventSet_Bus_Network_0
      EventStatusChanged_Bus_Network_0_72: upstream-reference=BusMon_SwCType_Prototype.Geltungsbereich_E3_1_2_Premium.EventStatusChanged_Bus_Network_0, ecu-extract-reference=BusMon_SwCType_Prototype.TopLevelCompositionPrototype.EventStatusChanged_Bus_Network_0
      RPORT_NWDF_Network_0_73: upstream-reference=BusMon_SwCType_Prototype.Geltungsbereich_E3_1_2_Premium.RPORT_NWDF_Network_0, ecu-extract-reference=BusMon_SwCType_Prototype.TopLevelCompositionPrototype.RPORT_NWDF_Network_0
      SI_NWDF_gueltig_74: upstream-reference=RPORT_NWDF_Network_0.BusMon_SwCType_Prototype.Geltungsbereich_E3_1_2_Premium.SI_NWDF_gueltig, ecu-extract-reference=RPORT_NWDF_Network_0.BusMon_SwCType_Prototype.TopLevelCompositionPrototype.SI_NWDF_gueltig
      SI_NWDF_75: upstream-reference=RPORT_NWDF_Network_0.BusMon_SwCType_Prototype.Geltungsbereich_E3_1_2_Premium.SI_NWDF, ecu-extract-reference=RPORT_NWDF_Network_0.BusMon_SwCType_Prototype.TopLevelCompositionPrototype.SI_NWDF
      EventSet_BusOff_Network_0_76: upstream-reference=BusMon_SwCType_Prototype.Geltungsbereich_E3_1_2_Premium.EventSet_BusOff_Network_0, ecu-extract-reference=BusMon_SwCType_Prototype.TopLevelCompositionPrototype.EventSet_BusOff_Network_0
      EventSet_NodeTimeout_Network_0_MonitoredNodes_0_77: upstream-reference=BusMon_SwCType_Prototype.Geltungsbereich_E3_1_2_Premium.EventSet_NodeTimeout_Network_0_MonitoredNodes_0, ecu-extract-reference=BusMon_SwCType_Prototype.TopLevelCompositionPrototype.EventSet_NodeTimeout_Network_0_MonitoredNodes_0
      EventStatusChanged_NodeTimeout_Network_0_MonitoredNodes_0_78: upstream-reference=BusMon_SwCType_Prototype.Geltungsbereich_E3_1_2_Premium.EventStatusChanged_NodeTimeout_Network_0_MonitoredNodes_0, ecu-extract-reference=BusMon_SwCType_Prototype.TopLevelCompositionPrototype.EventStatusChanged_NodeTimeout_Network_0_MonitoredNodes_0
      RPORT_Network_0_MonitoredNodes_0_79: upstream-reference=BusMon_SwCType_Prototype.Geltungsbereich_E3_1_2_Premium.RPORT_Network_0_MonitoredNodes_0, ecu-extract-reference=BusMon_SwCType_Prototype.TopLevelCompositionPrototype.RPORT_Network_0_MonitoredNodes_0
      VDP_SGRGS_Nachlauf_allg_XIX_RGS_Anf_01_XIX_Airbag_SUBCANFD01_316495133R_80: upstream-reference=RPORT_Network_0_MonitoredNodes_0.BusMon_SwCType_Prototype.Geltungsbereich_E3_1_2_Premium.VDP_SGRGS_Nachlauf_allg_XIX_RGS_Anf_01_XIX_Airbag_SUBCANFD01_316495133R, ecu-extract-reference=RPORT_Network_0_MonitoredNodes_0.BusMon_SwCType_Prototype.TopLevelCompositionPrototype.VDP_SGRGS_Nachlauf_allg_XIX_RGS_Anf_01_XIX_Airbag_SUBCANFD01_316495133R
      PNState_Network_0_MonitoredNodes_0_81: upstream-reference=BusMon_SwCType_Prototype.Geltungsbereich_E3_1_2_Premium.PNState_Network_0_MonitoredNodes_0, ecu-extract-reference=BusMon_SwCType_Prototype.TopLevelCompositionPrototype.PNState_Network_0_MonitoredNodes_0
      currentMode_82: upstream-reference=BusMon_SwCType_Prototype.Geltungsbereich_E3_1_2_Premium.currentMode, ecu-extract-reference=BusMon_SwCType_Prototype.TopLevelCompositionPrototype.currentMode
      VoltMon_Prototype_83: upstream-reference=Geltungsbereich_E3_1_2_Premium.VoltMon_Prototype, ecu-extract-reference=TopLevelCompositionPrototype.VoltMon_Prototype
      VMDtcVoltageMonitorCfg_OV_84: upstream-reference=VoltMon_Prototype.Geltungsbereich_E3_1_2_Premium.VMDtcVoltageMonitorCfg_OV, ecu-extract-reference=VoltMon_Prototype.TopLevelCompositionPrototype.VMDtcVoltageMonitorCfg_OV
      VMDtcVoltageMonitorCfg_UV_85: upstream-reference=VoltMon_Prototype.Geltungsbereich_E3_1_2_Premium.VMDtcVoltageMonitorCfg_UV, ecu-extract-reference=VoltMon_Prototype.TopLevelCompositionPrototype.VMDtcVoltageMonitorCfg_UV
      VMEcuMode_86: upstream-reference=VoltMon_Prototype.Geltungsbereich_E3_1_2_Premium.VMEcuMode, ecu-extract-reference=VoltMon_Prototype.TopLevelCompositionPrototype.VMEcuMode
      VMKl30Sense_87: upstream-reference=VoltMon_Prototype.Geltungsbereich_E3_1_2_Premium.VMKl30Sense, ecu-extract-reference=VoltMon_Prototype.TopLevelCompositionPrototype.VMKl30Sense
      VMModVoltageMonitorCfg_OV_88: upstream-reference=VoltMon_Prototype.Geltungsbereich_E3_1_2_Premium.VMModVoltageMonitorCfg_OV, ecu-extract-reference=VoltMon_Prototype.TopLevelCompositionPrototype.VMModVoltageMonitorCfg_OV
      VMModVoltageMonitorCfg_UV_89: upstream-reference=VoltMon_Prototype.Geltungsbereich_E3_1_2_Premium.VMModVoltageMonitorCfg_UV, ecu-extract-reference=VoltMon_Prototype.TopLevelCompositionPrototype.VMModVoltageMonitorCfg_UV
      TestSwc_90: upstream-reference=Geltungsbereich_E3_1_2_Premium.TestSwc, ecu-extract-reference=TopLevelCompositionPrototype.TestSwc
      P_KN_RGS_VL_BusKnockOut_91: upstream-reference=TestSwc.Geltungsbereich_E3_1_2_Premium.P_KN_RGS_VL_BusKnockOut, ecu-extract-reference=TestSwc.TopLevelCompositionPrototype.P_KN_RGS_VL_BusKnockOut
      KN_RGS_VL_BusKnockOut_92: upstream-reference=P_KN_RGS_VL_BusKnockOut.TestSwc.Geltungsbereich_E3_1_2_Premium.KN_RGS_VL_BusKnockOut, ecu-extract-reference=P_KN_RGS_VL_BusKnockOut.TestSwc.TopLevelCompositionPrototype.KN_RGS_VL_BusKnockOut
      P_KN_RGS_VL_BusKnockOutTimer_93: upstream-reference=TestSwc.Geltungsbereich_E3_1_2_Premium.P_KN_RGS_VL_BusKnockOutTimer, ecu-extract-reference=TestSwc.TopLevelCompositionPrototype.P_KN_RGS_VL_BusKnockOutTimer
      KN_RGS_VL_BusKnockOutTimer_94: upstream-reference=P_KN_RGS_VL_BusKnockOutTimer.TestSwc.Geltungsbereich_E3_1_2_Premium.KN_RGS_VL_BusKnockOutTimer, ecu-extract-reference=P_KN_RGS_VL_BusKnockOutTimer.TestSwc.TopLevelCompositionPrototype.KN_RGS_VL_BusKnockOutTimer
      P_KN_RGS_VL_ECUKnockOut_95: upstream-reference=TestSwc.Geltungsbereich_E3_1_2_Premium.P_KN_RGS_VL_ECUKnockOut, ecu-extract-reference=TestSwc.TopLevelCompositionPrototype.P_KN_RGS_VL_ECUKnockOut
      KN_RGS_VL_ECUKnockOut_96: upstream-reference=P_KN_RGS_VL_ECUKnockOut.TestSwc.Geltungsbereich_E3_1_2_Premium.KN_RGS_VL_ECUKnockOut, ecu-extract-reference=P_KN_RGS_VL_ECUKnockOut.TestSwc.TopLevelCompositionPrototype.KN_RGS_VL_ECUKnockOut
      P_KN_RGS_VL_ECUKnockOutTimer_97: upstream-reference=TestSwc.Geltungsbereich_E3_1_2_Premium.P_KN_RGS_VL_ECUKnockOutTimer, ecu-extract-reference=TestSwc.TopLevelCompositionPrototype.P_KN_RGS_VL_ECUKnockOutTimer
      KN_RGS_VL_ECUKnockOutTimer_98: upstream-reference=P_KN_RGS_VL_ECUKnockOutTimer.TestSwc.Geltungsbereich_E3_1_2_Premium.KN_RGS_VL_ECUKnockOutTimer, ecu-extract-reference=P_KN_RGS_VL_ECUKnockOutTimer.TestSwc.TopLevelCompositionPrototype.KN_RGS_VL_ECUKnockOutTimer
      P_NM_RGS_VL_CBV_AWB_99: upstream-reference=TestSwc.Geltungsbereich_E3_1_2_Premium.P_NM_RGS_VL_CBV_AWB, ecu-extract-reference=TestSwc.TopLevelCompositionPrototype.P_NM_RGS_VL_CBV_AWB
      NM_RGS_VL_CBV_AWB_100: upstream-reference=P_NM_RGS_VL_CBV_AWB.TestSwc.Geltungsbereich_E3_1_2_Premium.NM_RGS_VL_CBV_AWB, ecu-extract-reference=P_NM_RGS_VL_CBV_AWB.TestSwc.TopLevelCompositionPrototype.NM_RGS_VL_CBV_AWB
      P_NM_RGS_VL_CBV_CRI_101: upstream-reference=TestSwc.Geltungsbereich_E3_1_2_Premium.P_NM_RGS_VL_CBV_CRI, ecu-extract-reference=TestSwc.TopLevelCompositionPrototype.P_NM_RGS_VL_CBV_CRI
      NM_RGS_VL_CBV_CRI_102: upstream-reference=P_NM_RGS_VL_CBV_CRI.TestSwc.Geltungsbereich_E3_1_2_Premium.NM_RGS_VL_CBV_CRI, ecu-extract-reference=P_NM_RGS_VL_CBV_CRI.TestSwc.TopLevelCompositionPrototype.NM_RGS_VL_CBV_CRI
      P_NM_RGS_VL_FCAB_103: upstream-reference=TestSwc.Geltungsbereich_E3_1_2_Premium.P_NM_RGS_VL_FCAB, ecu-extract-reference=TestSwc.TopLevelCompositionPrototype.P_NM_RGS_VL_FCAB
      NM_RGS_VL_FCAB_104: upstream-reference=P_NM_RGS_VL_FCAB.TestSwc.Geltungsbereich_E3_1_2_Premium.NM_RGS_VL_FCAB, ecu-extract-reference=P_NM_RGS_VL_FCAB.TestSwc.TopLevelCompositionPrototype.NM_RGS_VL_FCAB
      P_NM_RGS_VL_FCIB_105: upstream-reference=TestSwc.Geltungsbereich_E3_1_2_Premium.P_NM_RGS_VL_FCIB, ecu-extract-reference=TestSwc.TopLevelCompositionPrototype.P_NM_RGS_VL_FCIB
      NM_RGS_VL_FCIB_106: upstream-reference=P_NM_RGS_VL_FCIB.TestSwc.Geltungsbereich_E3_1_2_Premium.NM_RGS_VL_FCIB, ecu-extract-reference=P_NM_RGS_VL_FCIB.TestSwc.TopLevelCompositionPrototype.NM_RGS_VL_FCIB
      P_NM_RGS_VL_NM_State_107: upstream-reference=TestSwc.Geltungsbereich_E3_1_2_Premium.P_NM_RGS_VL_NM_State, ecu-extract-reference=TestSwc.TopLevelCompositionPrototype.P_NM_RGS_VL_NM_State
      NM_RGS_VL_NM_State_108: upstream-reference=P_NM_RGS_VL_NM_State.TestSwc.Geltungsbereich_E3_1_2_Premium.NM_RGS_VL_NM_State, ecu-extract-reference=P_NM_RGS_VL_NM_State.TestSwc.TopLevelCompositionPrototype.NM_RGS_VL_NM_State
      P_NM_RGS_VL_NM_aktiv_Diag_109: upstream-reference=TestSwc.Geltungsbereich_E3_1_2_Premium.P_NM_RGS_VL_NM_aktiv_Diag, ecu-extract-reference=TestSwc.TopLevelCompositionPrototype.P_NM_RGS_VL_NM_aktiv_Diag
      NM_RGS_VL_NM_aktiv_Diag_110: upstream-reference=P_NM_RGS_VL_NM_aktiv_Diag.TestSwc.Geltungsbereich_E3_1_2_Premium.NM_RGS_VL_NM_aktiv_Diag, ecu-extract-reference=P_NM_RGS_VL_NM_aktiv_Diag.TestSwc.TopLevelCompositionPrototype.NM_RGS_VL_NM_aktiv_Diag
      P_NM_RGS_VL_NM_aktiv_KL15_111: upstream-reference=TestSwc.Geltungsbereich_E3_1_2_Premium.P_NM_RGS_VL_NM_aktiv_KL15, ecu-extract-reference=TestSwc.TopLevelCompositionPrototype.P_NM_RGS_VL_NM_aktiv_KL15
      NM_RGS_VL_NM_aktiv_KL15_112: upstream-reference=P_NM_RGS_VL_NM_aktiv_KL15.TestSwc.Geltungsbereich_E3_1_2_Premium.NM_RGS_VL_NM_aktiv_KL15, ecu-extract-reference=P_NM_RGS_VL_NM_aktiv_KL15.TestSwc.TopLevelCompositionPrototype.NM_RGS_VL_NM_aktiv_KL15
      P_NM_RGS_VL_NM_aktiv_Mot_aktiv_113: upstream-reference=TestSwc.Geltungsbereich_E3_1_2_Premium.P_NM_RGS_VL_NM_aktiv_Mot_aktiv, ecu-extract-reference=TestSwc.TopLevelCompositionPrototype.P_NM_RGS_VL_NM_aktiv_Mot_aktiv
      NM_RGS_VL_NM_aktiv_Mot_aktiv_114: upstream-reference=P_NM_RGS_VL_NM_aktiv_Mot_aktiv.TestSwc.Geltungsbereich_E3_1_2_Premium.NM_RGS_VL_NM_aktiv_Mot_aktiv, ecu-extract-reference=P_NM_RGS_VL_NM_aktiv_Mot_aktiv.TestSwc.TopLevelCompositionPrototype.NM_RGS_VL_NM_aktiv_Mot_aktiv
      P_NM_RGS_VL_NM_aktiv_Tmin_115: upstream-reference=TestSwc.Geltungsbereich_E3_1_2_Premium.P_NM_RGS_VL_NM_aktiv_Tmin, ecu-extract-reference=TestSwc.TopLevelCompositionPrototype.P_NM_RGS_VL_NM_aktiv_Tmin
      NM_RGS_VL_NM_aktiv_Tmin_116: upstream-reference=P_NM_RGS_VL_NM_aktiv_Tmin.TestSwc.Geltungsbereich_E3_1_2_Premium.NM_RGS_VL_NM_aktiv_Tmin, ecu-extract-reference=P_NM_RGS_VL_NM_aktiv_Tmin.TestSwc.TopLevelCompositionPrototype.NM_RGS_VL_NM_aktiv_Tmin
      P_NM_RGS_VL_SNI_10_117: upstream-reference=TestSwc.Geltungsbereich_E3_1_2_Premium.P_NM_RGS_VL_SNI_10, ecu-extract-reference=TestSwc.TopLevelCompositionPrototype.P_NM_RGS_VL_SNI_10
      NM_RGS_VL_SNI_10_118: upstream-reference=P_NM_RGS_VL_SNI_10.TestSwc.Geltungsbereich_E3_1_2_Premium.NM_RGS_VL_SNI_10, ecu-extract-reference=P_NM_RGS_VL_SNI_10.TestSwc.TopLevelCompositionPrototype.NM_RGS_VL_SNI_10
      P_NM_RGS_VL_UDS_CC_119: upstream-reference=TestSwc.Geltungsbereich_E3_1_2_Premium.P_NM_RGS_VL_UDS_CC, ecu-extract-reference=TestSwc.TopLevelCompositionPrototype.P_NM_RGS_VL_UDS_CC
      NM_RGS_VL_UDS_CC_120: upstream-reference=P_NM_RGS_VL_UDS_CC.TestSwc.Geltungsbereich_E3_1_2_Premium.NM_RGS_VL_UDS_CC, ecu-extract-reference=P_NM_RGS_VL_UDS_CC.TestSwc.TopLevelCompositionPrototype.NM_RGS_VL_UDS_CC
      P_NM_RGS_VL_Wakeup_121: upstream-reference=TestSwc.Geltungsbereich_E3_1_2_Premium.P_NM_RGS_VL_Wakeup, ecu-extract-reference=TestSwc.TopLevelCompositionPrototype.P_NM_RGS_VL_Wakeup
      NM_RGS_VL_Wakeup_122: upstream-reference=P_NM_RGS_VL_Wakeup.TestSwc.Geltungsbereich_E3_1_2_Premium.NM_RGS_VL_Wakeup, ecu-extract-reference=P_NM_RGS_VL_Wakeup.TestSwc.TopLevelCompositionPrototype.NM_RGS_VL_Wakeup
      P_RGS_VL_Abschaltstufe_123: upstream-reference=TestSwc.Geltungsbereich_E3_1_2_Premium.P_RGS_VL_Abschaltstufe, ecu-extract-reference=TestSwc.TopLevelCompositionPrototype.P_RGS_VL_Abschaltstufe
      RGS_VL_Abschaltstufe_124: upstream-reference=P_RGS_VL_Abschaltstufe.TestSwc.Geltungsbereich_E3_1_2_Premium.RGS_VL_Abschaltstufe, ecu-extract-reference=P_RGS_VL_Abschaltstufe.TestSwc.TopLevelCompositionPrototype.RGS_VL_Abschaltstufe
      P_RGS_VL_Bauteilfehler_125: upstream-reference=TestSwc.Geltungsbereich_E3_1_2_Premium.P_RGS_VL_Bauteilfehler, ecu-extract-reference=TestSwc.TopLevelCompositionPrototype.P_RGS_VL_Bauteilfehler
      RGS_VL_Bauteilfehler_126: upstream-reference=P_RGS_VL_Bauteilfehler.TestSwc.Geltungsbereich_E3_1_2_Premium.RGS_VL_Bauteilfehler, ecu-extract-reference=P_RGS_VL_Bauteilfehler.TestSwc.TopLevelCompositionPrototype.RGS_VL_Bauteilfehler
      P_RGS_VL_Crashabschaltung_127: upstream-reference=TestSwc.Geltungsbereich_E3_1_2_Premium.P_RGS_VL_Crashabschaltung, ecu-extract-reference=TestSwc.TopLevelCompositionPrototype.P_RGS_VL_Crashabschaltung
      RGS_VL_Crashabschaltung_128: upstream-reference=P_RGS_VL_Crashabschaltung.TestSwc.Geltungsbereich_E3_1_2_Premium.RGS_VL_Crashabschaltung, ecu-extract-reference=P_RGS_VL_Crashabschaltung.TestSwc.TopLevelCompositionPrototype.RGS_VL_Crashabschaltung
      P_RGS_VL_EEPROM_Datensatzfehler_129: upstream-reference=TestSwc.Geltungsbereich_E3_1_2_Premium.P_RGS_VL_EEPROM_Datensatzfehler, ecu-extract-reference=TestSwc.TopLevelCompositionPrototype.P_RGS_VL_EEPROM_Datensatzfehler
      RGS_VL_EEPROM_Datensatzfehler_130: upstream-reference=P_RGS_VL_EEPROM_Datensatzfehler.TestSwc.Geltungsbereich_E3_1_2_Premium.RGS_VL_EEPROM_Datensatzfehler, ecu-extract-reference=P_RGS_VL_EEPROM_Datensatzfehler.TestSwc.TopLevelCompositionPrototype.RGS_VL_EEPROM_Datensatzfehler
      P_RGS_VL_Gurtbandauszug_131: upstream-reference=TestSwc.Geltungsbereich_E3_1_2_Premium.P_RGS_VL_Gurtbandauszug, ecu-extract-reference=TestSwc.TopLevelCompositionPrototype.P_RGS_VL_Gurtbandauszug
      RGS_VL_Gurtbandauszug_132: upstream-reference=P_RGS_VL_Gurtbandauszug.TestSwc.Geltungsbereich_E3_1_2_Premium.RGS_VL_Gurtbandauszug, ecu-extract-reference=P_RGS_VL_Gurtbandauszug.TestSwc.TopLevelCompositionPrototype.RGS_VL_Gurtbandauszug
      P_RGS_VL_Gurtgeschwindigkeit_133: upstream-reference=TestSwc.Geltungsbereich_E3_1_2_Premium.P_RGS_VL_Gurtgeschwindigkeit, ecu-extract-reference=TestSwc.TopLevelCompositionPrototype.P_RGS_VL_Gurtgeschwindigkeit
      RGS_VL_Gurtgeschwindigkeit_134: upstream-reference=P_RGS_VL_Gurtgeschwindigkeit.TestSwc.Geltungsbereich_E3_1_2_Premium.RGS_VL_Gurtgeschwindigkeit, ecu-extract-reference=P_RGS_VL_Gurtgeschwindigkeit.TestSwc.TopLevelCompositionPrototype.RGS_VL_Gurtgeschwindigkeit
      P_RGS_VL_InPos_135: upstream-reference=TestSwc.Geltungsbereich_E3_1_2_Premium.P_RGS_VL_InPos, ecu-extract-reference=TestSwc.TopLevelCompositionPrototype.P_RGS_VL_InPos
      RGS_VL_InPos_136: upstream-reference=P_RGS_VL_InPos.TestSwc.Geltungsbereich_E3_1_2_Premium.RGS_VL_InPos, ecu-extract-reference=P_RGS_VL_InPos.TestSwc.TopLevelCompositionPrototype.RGS_VL_InPos
      P_RGS_VL_KD_Fehler_137: upstream-reference=TestSwc.Geltungsbereich_E3_1_2_Premium.P_RGS_VL_KD_Fehler, ecu-extract-reference=TestSwc.TopLevelCompositionPrototype.P_RGS_VL_KD_Fehler
      RGS_VL_KD_Fehler_138: upstream-reference=P_RGS_VL_KD_Fehler.TestSwc.Geltungsbereich_E3_1_2_Premium.RGS_VL_KD_Fehler, ecu-extract-reference=P_RGS_VL_KD_Fehler.TestSwc.TopLevelCompositionPrototype.RGS_VL_KD_Fehler
      P_RGS_VL_Kommunikationsfehler_ASG_139: upstream-reference=TestSwc.Geltungsbereich_E3_1_2_Premium.P_RGS_VL_Kommunikationsfehler_ASG, ecu-extract-reference=TestSwc.TopLevelCompositionPrototype.P_RGS_VL_Kommunikationsfehler_ASG
      RGS_VL_Kommunikationsfehler_ASG_140: upstream-reference=P_RGS_VL_Kommunikationsfehler_ASG.TestSwc.Geltungsbereich_E3_1_2_Premium.RGS_VL_Kommunikationsfehler_ASG, ecu-extract-reference=P_RGS_VL_Kommunikationsfehler_ASG.TestSwc.TopLevelCompositionPrototype.RGS_VL_Kommunikationsfehler_ASG
      P_RGS_VL_KompSchutz_141: upstream-reference=TestSwc.Geltungsbereich_E3_1_2_Premium.P_RGS_VL_KompSchutz, ecu-extract-reference=TestSwc.TopLevelCompositionPrototype.P_RGS_VL_KompSchutz
      RGS_VL_KompSchutz_142: upstream-reference=P_RGS_VL_KompSchutz.TestSwc.Geltungsbereich_E3_1_2_Premium.RGS_VL_KompSchutz, ecu-extract-reference=P_RGS_VL_KompSchutz.TestSwc.TopLevelCompositionPrototype.RGS_VL_KompSchutz
      P_RGS_VL_Lokalaktiv_143: upstream-reference=TestSwc.Geltungsbereich_E3_1_2_Premium.P_RGS_VL_Lokalaktiv, ecu-extract-reference=TestSwc.TopLevelCompositionPrototype.P_RGS_VL_Lokalaktiv
      RGS_VL_Lokalaktiv_144: upstream-reference=P_RGS_VL_Lokalaktiv.TestSwc.Geltungsbereich_E3_1_2_Premium.RGS_VL_Lokalaktiv, ecu-extract-reference=P_RGS_VL_Lokalaktiv.TestSwc.TopLevelCompositionPrototype.RGS_VL_Lokalaktiv
      P_RGS_VL_Max_Gurtlosezyklen_145: upstream-reference=TestSwc.Geltungsbereich_E3_1_2_Premium.P_RGS_VL_Max_Gurtlosezyklen, ecu-extract-reference=TestSwc.TopLevelCompositionPrototype.P_RGS_VL_Max_Gurtlosezyklen
      RGS_VL_Max_Gurtlosezyklen_146: upstream-reference=P_RGS_VL_Max_Gurtlosezyklen.TestSwc.Geltungsbereich_E3_1_2_Premium.RGS_VL_Max_Gurtlosezyklen, ecu-extract-reference=P_RGS_VL_Max_Gurtlosezyklen.TestSwc.TopLevelCompositionPrototype.RGS_VL_Max_Gurtlosezyklen
      P_RGS_VL_Max_Haptikzyklenfehler_147: upstream-reference=TestSwc.Geltungsbereich_E3_1_2_Premium.P_RGS_VL_Max_Haptikzyklenfehler, ecu-extract-reference=TestSwc.TopLevelCompositionPrototype.P_RGS_VL_Max_Haptikzyklenfehler
      RGS_VL_Max_Haptikzyklenfehler_148: upstream-reference=P_RGS_VL_Max_Haptikzyklenfehler.TestSwc.Geltungsbereich_E3_1_2_Premium.RGS_VL_Max_Haptikzyklenfehler, ecu-extract-reference=P_RGS_VL_Max_Haptikzyklenfehler.TestSwc.TopLevelCompositionPrototype.RGS_VL_Max_Haptikzyklenfehler
      P_RGS_VL_Max_Straffzyklenfehler_149: upstream-reference=TestSwc.Geltungsbereich_E3_1_2_Premium.P_RGS_VL_Max_Straffzyklenfehler, ecu-extract-reference=TestSwc.TopLevelCompositionPrototype.P_RGS_VL_Max_Straffzyklenfehler
      RGS_VL_Max_Straffzyklenfehler_150: upstream-reference=P_RGS_VL_Max_Straffzyklenfehler.TestSwc.Geltungsbereich_E3_1_2_Premium.RGS_VL_Max_Straffzyklenfehler, ecu-extract-reference=P_RGS_VL_Max_Straffzyklenfehler.TestSwc.TopLevelCompositionPrototype.RGS_VL_Max_Straffzyklenfehler
      P_RGS_VL_Motorfehler_151: upstream-reference=TestSwc.Geltungsbereich_E3_1_2_Premium.P_RGS_VL_Motorfehler, ecu-extract-reference=TestSwc.TopLevelCompositionPrototype.P_RGS_VL_Motorfehler
      RGS_VL_Motorfehler_152: upstream-reference=P_RGS_VL_Motorfehler.TestSwc.Geltungsbereich_E3_1_2_Premium.RGS_VL_Motorfehler, ecu-extract-reference=P_RGS_VL_Motorfehler.TestSwc.TopLevelCompositionPrototype.RGS_VL_Motorfehler
      P_RGS_VL_Nachlauftyp_153: upstream-reference=TestSwc.Geltungsbereich_E3_1_2_Premium.P_RGS_VL_Nachlauftyp, ecu-extract-reference=TestSwc.TopLevelCompositionPrototype.P_RGS_VL_Nachlauftyp
      RGS_VL_Nachlauftyp_154: upstream-reference=P_RGS_VL_Nachlauftyp.TestSwc.Geltungsbereich_E3_1_2_Premium.RGS_VL_Nachlauftyp, ecu-extract-reference=P_RGS_VL_Nachlauftyp.TestSwc.TopLevelCompositionPrototype.RGS_VL_Nachlauftyp
      P_RGS_VL_SNI_10_155: upstream-reference=TestSwc.Geltungsbereich_E3_1_2_Premium.P_RGS_VL_SNI_10, ecu-extract-reference=TestSwc.TopLevelCompositionPrototype.P_RGS_VL_SNI_10
      RGS_VL_SNI_10_156: upstream-reference=P_RGS_VL_SNI_10.TestSwc.Geltungsbereich_E3_1_2_Premium.RGS_VL_SNI_10, ecu-extract-reference=P_RGS_VL_SNI_10.TestSwc.TopLevelCompositionPrototype.RGS_VL_SNI_10
      P_RGS_VL_Status_157: upstream-reference=TestSwc.Geltungsbereich_E3_1_2_Premium.P_RGS_VL_Status, ecu-extract-reference=TestSwc.TopLevelCompositionPrototype.P_RGS_VL_Status
      RGS_VL_Status_158: upstream-reference=P_RGS_VL_Status.TestSwc.Geltungsbereich_E3_1_2_Premium.RGS_VL_Status, ecu-extract-reference=P_RGS_VL_Status.TestSwc.TopLevelCompositionPrototype.RGS_VL_Status
      P_RGS_VL_Strom_159: upstream-reference=TestSwc.Geltungsbereich_E3_1_2_Premium.P_RGS_VL_Strom, ecu-extract-reference=TestSwc.TopLevelCompositionPrototype.P_RGS_VL_Strom
      RGS_VL_Strom_160: upstream-reference=P_RGS_VL_Strom.TestSwc.Geltungsbereich_E3_1_2_Premium.RGS_VL_Strom, ecu-extract-reference=P_RGS_VL_Strom.TestSwc.TopLevelCompositionPrototype.RGS_VL_Strom
      P_RGS_VL_Subsystemaktiv_161: upstream-reference=TestSwc.Geltungsbereich_E3_1_2_Premium.P_RGS_VL_Subsystemaktiv, ecu-extract-reference=TestSwc.TopLevelCompositionPrototype.P_RGS_VL_Subsystemaktiv
      RGS_VL_Subsystemaktiv_162: upstream-reference=P_RGS_VL_Subsystemaktiv.TestSwc.Geltungsbereich_E3_1_2_Premium.RGS_VL_Subsystemaktiv, ecu-extract-reference=P_RGS_VL_Subsystemaktiv.TestSwc.TopLevelCompositionPrototype.RGS_VL_Subsystemaktiv
      P_RGS_VL_Temp_163: upstream-reference=TestSwc.Geltungsbereich_E3_1_2_Premium.P_RGS_VL_Temp, ecu-extract-reference=TestSwc.TopLevelCompositionPrototype.P_RGS_VL_Temp
      RGS_VL_Temp_164: upstream-reference=P_RGS_VL_Temp.TestSwc.Geltungsbereich_E3_1_2_Premium.RGS_VL_Temp, ecu-extract-reference=P_RGS_VL_Temp.TestSwc.TopLevelCompositionPrototype.RGS_VL_Temp
      P_RGS_VL_Transport_Mode_165: upstream-reference=TestSwc.Geltungsbereich_E3_1_2_Premium.P_RGS_VL_Transport_Mode, ecu-extract-reference=TestSwc.TopLevelCompositionPrototype.P_RGS_VL_Transport_Mode
      RGS_VL_Transport_Mode_166: upstream-reference=P_RGS_VL_Transport_Mode.TestSwc.Geltungsbereich_E3_1_2_Premium.RGS_VL_Transport_Mode, ecu-extract-reference=P_RGS_VL_Transport_Mode.TestSwc.TopLevelCompositionPrototype.RGS_VL_Transport_Mode
      P_RGS_VL_Ueberspannung_167: upstream-reference=TestSwc.Geltungsbereich_E3_1_2_Premium.P_RGS_VL_Ueberspannung, ecu-extract-reference=TestSwc.TopLevelCompositionPrototype.P_RGS_VL_Ueberspannung
      RGS_VL_Ueberspannung_168: upstream-reference=P_RGS_VL_Ueberspannung.TestSwc.Geltungsbereich_E3_1_2_Premium.RGS_VL_Ueberspannung, ecu-extract-reference=P_RGS_VL_Ueberspannung.TestSwc.TopLevelCompositionPrototype.RGS_VL_Ueberspannung
      P_RGS_VL_Uebertemperatur_defekt_169: upstream-reference=TestSwc.Geltungsbereich_E3_1_2_Premium.P_RGS_VL_Uebertemperatur_defekt, ecu-extract-reference=TestSwc.TopLevelCompositionPrototype.P_RGS_VL_Uebertemperatur_defekt
      RGS_VL_Uebertemperatur_defekt_170: upstream-reference=P_RGS_VL_Uebertemperatur_defekt.TestSwc.Geltungsbereich_E3_1_2_Premium.RGS_VL_Uebertemperatur_defekt, ecu-extract-reference=P_RGS_VL_Uebertemperatur_defekt.TestSwc.TopLevelCompositionPrototype.RGS_VL_Uebertemperatur_defekt
      P_RGS_VL_Unterspannung_171: upstream-reference=TestSwc.Geltungsbereich_E3_1_2_Premium.P_RGS_VL_Unterspannung, ecu-extract-reference=TestSwc.TopLevelCompositionPrototype.P_RGS_VL_Unterspannung
      RGS_VL_Unterspannung_172: upstream-reference=P_RGS_VL_Unterspannung.TestSwc.Geltungsbereich_E3_1_2_Premium.RGS_VL_Unterspannung, ecu-extract-reference=P_RGS_VL_Unterspannung.TestSwc.TopLevelCompositionPrototype.RGS_VL_Unterspannung
      P_RGS_VL_keineStraffungUeberspg_173: upstream-reference=TestSwc.Geltungsbereich_E3_1_2_Premium.P_RGS_VL_keineStraffungUeberspg, ecu-extract-reference=TestSwc.TopLevelCompositionPrototype.P_RGS_VL_keineStraffungUeberspg
      RGS_VL_keineStraffungUeberspg_174: upstream-reference=P_RGS_VL_keineStraffungUeberspg.TestSwc.Geltungsbereich_E3_1_2_Premium.RGS_VL_keineStraffungUeberspg, ecu-extract-reference=P_RGS_VL_keineStraffungUeberspg.TestSwc.TopLevelCompositionPrototype.RGS_VL_keineStraffungUeberspg
      P_RGS_VL_keineStraffungUnterspg_175: upstream-reference=TestSwc.Geltungsbereich_E3_1_2_Premium.P_RGS_VL_keineStraffungUnterspg, ecu-extract-reference=TestSwc.TopLevelCompositionPrototype.P_RGS_VL_keineStraffungUnterspg
      RGS_VL_keineStraffungUnterspg_176: upstream-reference=P_RGS_VL_keineStraffungUnterspg.TestSwc.Geltungsbereich_E3_1_2_Premium.RGS_VL_keineStraffungUnterspg, ecu-extract-reference=P_RGS_VL_keineStraffungUnterspg.TestSwc.TopLevelCompositionPrototype.RGS_VL_keineStraffungUnterspg
      P_RGS_VL_nicht_programmiert_177: upstream-reference=TestSwc.Geltungsbereich_E3_1_2_Premium.P_RGS_VL_nicht_programmiert, ecu-extract-reference=TestSwc.TopLevelCompositionPrototype.P_RGS_VL_nicht_programmiert
      RGS_VL_nicht_programmiert_178: upstream-reference=P_RGS_VL_nicht_programmiert.TestSwc.Geltungsbereich_E3_1_2_Premium.RGS_VL_nicht_programmiert, ecu-extract-reference=P_RGS_VL_nicht_programmiert.TestSwc.TopLevelCompositionPrototype.RGS_VL_nicht_programmiert
      R_NM_Airbag_01_FCAB_179: upstream-reference=TestSwc.Geltungsbereich_E3_1_2_Premium.R_NM_Airbag_01_FCAB, ecu-extract-reference=TestSwc.TopLevelCompositionPrototype.R_NM_Airbag_01_FCAB
      NM_Airbag_01_FCAB_180: upstream-reference=R_NM_Airbag_01_FCAB.TestSwc.Geltungsbereich_E3_1_2_Premium.NM_Airbag_01_FCAB, ecu-extract-reference=R_NM_Airbag_01_FCAB.TestSwc.TopLevelCompositionPrototype.NM_Airbag_01_FCAB
      R_RGS_Nachlauf_allg_181: upstream-reference=TestSwc.Geltungsbereich_E3_1_2_Premium.R_RGS_Nachlauf_allg, ecu-extract-reference=TestSwc.TopLevelCompositionPrototype.R_RGS_Nachlauf_allg
      RGS_Nachlauf_allg_182: upstream-reference=R_RGS_Nachlauf_allg.TestSwc.Geltungsbereich_E3_1_2_Premium.RGS_Nachlauf_allg, ecu-extract-reference=R_RGS_Nachlauf_allg.TestSwc.TopLevelCompositionPrototype.RGS_Nachlauf_allg
      R_RGS_VL_Anforderung_183: upstream-reference=TestSwc.Geltungsbereich_E3_1_2_Premium.R_RGS_VL_Anforderung, ecu-extract-reference=TestSwc.TopLevelCompositionPrototype.R_RGS_VL_Anforderung
      RGS_VL_Anforderung_184: upstream-reference=R_RGS_VL_Anforderung.TestSwc.Geltungsbereich_E3_1_2_Premium.RGS_VL_Anforderung, ecu-extract-reference=R_RGS_VL_Anforderung.TestSwc.TopLevelCompositionPrototype.RGS_VL_Anforderung
      R_RGS_VL_Nachlauf_2_185: upstream-reference=TestSwc.Geltungsbereich_E3_1_2_Premium.R_RGS_VL_Nachlauf_2, ecu-extract-reference=TestSwc.TopLevelCompositionPrototype.R_RGS_VL_Nachlauf_2
      RGS_VL_Nachlauf_2_186: upstream-reference=R_RGS_VL_Nachlauf_2.TestSwc.Geltungsbereich_E3_1_2_Premium.RGS_VL_Nachlauf_2, ecu-extract-reference=R_RGS_VL_Nachlauf_2.TestSwc.TopLevelCompositionPrototype.RGS_VL_Nachlauf_2
